# MSP430FR5969 register map
Vendor: msp430gen; File version: v0.4.0-24-gb954137
Registers are 16-bit, read-write, reset 0x0 unless marked. A register's access mark holds for its fields unless they carry their own. Offsets are from the block's base; [hi:lo] are bit positions; {n}, {i} and the like mark numbered series; 'fields as' and 'values as' point back to an identical list.

## CAPACITIVE_TOUCH_IO_0
Base 0x0000043E
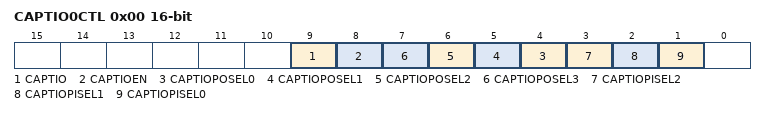
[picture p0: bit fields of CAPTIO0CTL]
0x00 CAPTIO0CTL — Capacitive_Touch_IO 0 control register
  [9] CAPTIO — CapTouchIO state
  [8] CAPTIOEN — CapTouchIO Enable
  [n+4] CAPTIOPOSEL{n} (n=0..3) — CapTouchIO Port Select Bit: {n}
  [3] CAPTIOPISEL2 — CapTouchIO Pin Select Bit: 2
  [2] CAPTIOPISEL1 — CapTouchIO Pin Select Bit: 1
  [1] CAPTIOPISEL0 — CapTouchIO Pin Select Bit: 0

## TIMER_3_A2
Base 0x00000440
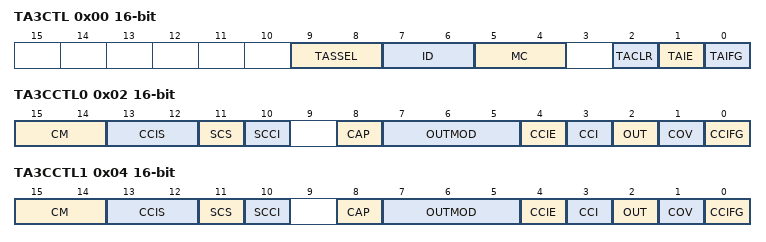
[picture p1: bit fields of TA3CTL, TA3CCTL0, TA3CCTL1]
0x00 TA3CTL — Timer3_A2 Control
  [9:8] TASSEL — Timer A clock source select 1
    0=Timer A clock source select: 0 - TACLK; 1=Timer A clock source select: 1 - ACLK; 2=Timer A clock source select: 2 - SMCLK; 3=Timer A clock source select: 3 - INCLK
  [7:6] ID — Timer A clock input divider 1
    0=Timer A input divider: 0 - /1; 1=Timer A input divider: 1 - /2; 2=Timer A input divider: 2 - /4; 3=Timer A input divider: 3 - /8
  [5:4] MC — Timer A mode control 1
    0=Timer A mode control: 0 - Stop; 1=Timer A mode control: 1 - Up to CCR0; 2=Timer A mode control: 2 - Continuous up; 3=Timer A mode control: 3 - Up/Down
  [2] TACLR — Timer A counter clear
  [1] TAIE — Timer A counter interrupt enable
  [0] TAIFG — Timer A counter interrupt flag
0x02 TA3CCTL0 — Timer3_A2 Capture/Compare Control 0
  [15:14] CM — Capture mode 1
    0=Capture mode: 0 - disabled; 1=Capture mode: 1 - pos. edge; 2=Capture mode: 1 - neg. edge; 3=Capture mode: 1 - both edges
  [13:12] CCIS — Capture input select 1
    0=Capture input select: 0 - CCIxA; 1=Capture input select: 1 - CCIxB; 2=Capture input select: 2 - GND; 3=Capture input select: 3 - Vcc
  [11] SCS — Capture sychronize
  [10] SCCI — Latched capture signal (read)
  [8] CAP — Capture mode: 1 /Compare mode : 0
  [7:5] OUTMOD — Output mode 2
    0=PWM output mode: 0 - output only; 1=PWM output mode: 1 - set; 2=PWM output mode: 2 - PWM toggle/reset; 3=PWM output mode: 3 - PWM set/reset; 4=PWM output mode: 4 - toggle; 5=PWM output mode: 5 - Reset; 6=PWM output mode: 6 - PWM toggle/set; 7=PWM output mode: 7 - PWM reset/set
  [4] CCIE — Capture/compare interrupt enable
  [3] CCI — Capture input signal (read)
  [2] OUT — PWM Output signal if output mode 0
  [1] COV — Capture/compare overflow flag
  [0] CCIFG — Capture/compare interrupt flag
0x04 TA3CCTL1 — Timer3_A2 Capture/Compare Control 1
  fields as TA3CCTL0
0x10 TA3R — Timer3_A2
0x12 TA3CCR0 — Timer3_A2 Capture/Compare 0
0x14 TA3CCR1 — Timer3_A2 Capture/Compare 1
0x20 TA3EX0 — Timer3_A2 Expansion Register 0
  [2:0] TAIDEX — Timer A Input divider expansion Bit: 0
    {v}=Timer A Input divider expansion : /{v+1} (v=0..7)
0x2E TA3IV — Timer3_A2 Interrupt Vector Word

## CAPACITIVE_TOUCH_IO_1
Base 0x0000047E
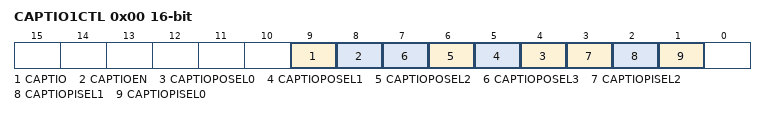
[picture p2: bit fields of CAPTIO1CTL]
0x00 CAPTIO1CTL — Capacitive_Touch_IO 1 control register
  [9] CAPTIO — CapTouchIO state
  [8] CAPTIOEN — CapTouchIO Enable
  [n+4] CAPTIOPOSEL{n} (n=0..3) — CapTouchIO Port Select Bit: {n}
  [3] CAPTIOPISEL2 — CapTouchIO Pin Select Bit: 2
  [2] CAPTIOPISEL1 — CapTouchIO Pin Select Bit: 1
  [1] CAPTIOPISEL0 — CapTouchIO Pin Select Bit: 0

## MPY_16 — MPY 16 Multiplier 16 Bit Mode
Base 0x000004C0
0x00 MPY — Multiply Unsigned/Operand 1
0x02 MPYS — Multiply Signed/Operand 1
0x04 MAC — Multiply Unsigned and Accumulate/Operand 1
0x06 MACS — Multiply Signed and Accumulate/Operand 1
0x08 OP2 — Operand 2
0x0A RESLO — Result Low Word
0x0C RESHI — Result High Word
0x0E SUMEXT — Sum Extend
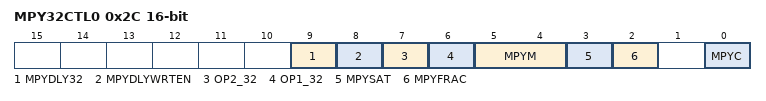
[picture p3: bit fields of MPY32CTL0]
0x2C MPY32CTL0 — MPY32 Control Register 0
  [9] MPYDLY32 — Delayed write mode
  [8] MPYDLYWRTEN — Delayed write enable
  [7] OP2_32 — Bit-width of operand 2 0:16Bit / 1:32Bit
  [6] OP1_32 — Bit-width of operand 1 0:16Bit / 1:32Bit
  [5:4] MPYM — Multiplier mode Bit:0
    0=Multiplier mode: MPY; 1=Multiplier mode: MPYS; 2=Multiplier mode: MAC; 3=Multiplier mode: MACS
  [3] MPYSAT — Saturation mode
  [2] MPYFRAC — Fractional mode
  [0] MPYC — Carry of the multiplier
